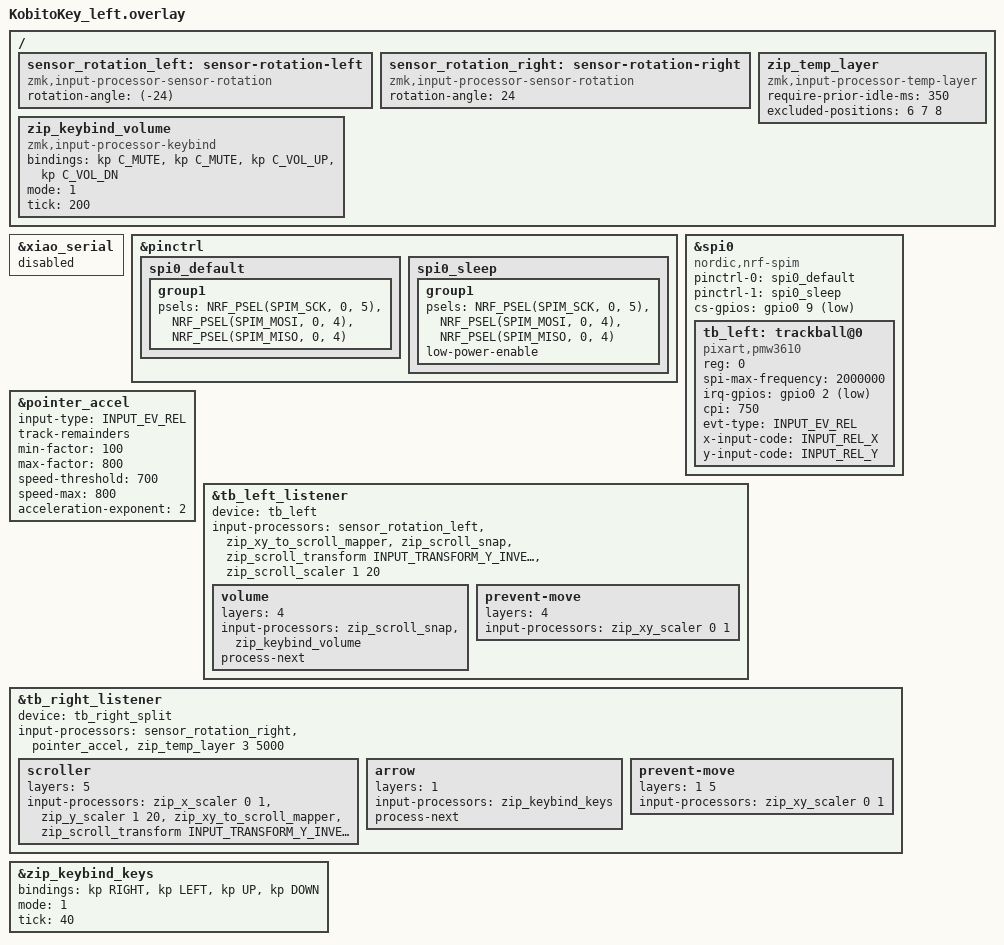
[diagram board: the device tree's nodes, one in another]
#include "kobitokey.dtsi"
#include <zephyr/dt-bindings/input/input-event-codes.h>
#include <input/processors.dtsi>
#include <input/processors/sensor_rotation.dtsi>
#include <behaviors/input_gestures_accel.dtsi>
#include <scroll-snap.dtsi>
#include <input/processors/zmk-input-processor-keybind.dtsi>

&xiao_serial { status = "disabled"; };

&pinctrl {
    spi0_default: spi0_default {
        group1 {
            psels = <NRF_PSEL(SPIM_SCK,  0, 5)>,
                    <NRF_PSEL(SPIM_MOSI, 0, 4)>,
                    <NRF_PSEL(SPIM_MISO, 0, 4)>;
        };
    };
    spi0_sleep: spi0_sleep {
        group1 {
            psels = <NRF_PSEL(SPIM_SCK,  0, 5)>,
                    <NRF_PSEL(SPIM_MOSI, 0, 4)>,
                    <NRF_PSEL(SPIM_MISO, 0, 4)>;
            low-power-enable;
        };
    };
};

&spi0 {
    status = "okay";
    compatible = "nordic,nrf-spim";
    pinctrl-0 = <&spi0_default>;
    pinctrl-1 = <&spi0_sleep>;
    pinctrl-names = "default", "sleep";
    cs-gpios = <&gpio0 9 GPIO_ACTIVE_LOW>;

    tb_left: trackball@0 {
        status = "okay";
        compatible = "pixart,pmw3610";
        reg = <0>;
        spi-max-frequency = <2000000>;
        irq-gpios = <&gpio0 2 (GPIO_ACTIVE_LOW | GPIO_PULL_UP)>;
        cpi = <750>; /* センサー感度 */

        evt-type = <INPUT_EV_REL>;
        x-input-code = <INPUT_REL_X>;
        y-input-code = <INPUT_REL_Y>;
    };
};

/ {
    sensor_rotation_left: sensor-rotation-left {
        compatible = "zmk,input-processor-sensor-rotation";
        status = "okay";
        #input-processor-cells = <0>;
        rotation-angle = <(-24)>;
    };

    sensor_rotation_right: sensor-rotation-right {
        compatible = "zmk,input-processor-sensor-rotation";
        #input-processor-cells = <0>;
        status = "okay";
        rotation-angle = <24>;
    };
};

&pointer_accel {
    input-type = <INPUT_EV_REL>;
    track-remainders;
    min-factor = <100>;
    max-factor = <800>;
    speed-threshold = <700>;
    speed-max = <800>;
    acceleration-exponent = <2>;
};

&tb_left_listener {
    status = "okay";
    device = <&tb_left>;

    input-processors =
            <&sensor_rotation_left>,
            <&zip_xy_to_scroll_mapper>,
            <&zip_scroll_snap>,
            <&zip_scroll_transform INPUT_TRANSFORM_Y_INVERT>,
            <&zip_scroll_scaler 1 20>;

    volume {
        layers = <4>;
        input-processors =
            <&zip_scroll_snap>,
            <&zip_keybind_volume>;
        process-next;
    };

    prevent-move {
        layers = <4>;
        input-processors = <&zip_xy_scaler 0 1>;
    };
};

/ {
  zip_keybind_volume: zip_keybind_volume {
    compatible = "zmk,input-processor-keybind";
    #input-processor-cells = <0>;
    bindings = <&kp C_MUTE>, <&kp C_MUTE>, <&kp C_VOL_UP>, <&kp C_VOL_DN>;
    mode = <1>;
    tick = <200>;
  };

  /omit-if-no-ref/ zip_temp_layer: zip_temp_layer {
    compatible = "zmk,input-processor-temp-layer";
    #input-processor-cells = <2>;
    require-prior-idle-ms = <350>;
  };
};

&tb_right_listener {
    status = "okay";
    device = <&tb_right_split>;

    input-processors =
        <&sensor_rotation_right>,
        <&pointer_accel>,
        <&zip_temp_layer 3 5000>; /* オートマウスレイヤーの指定とトラボ操作及びマウスボタン押下後に滞留する時間 */

    scroller {
        layers = <5>;
        input-processors =
            <&zip_x_scaler 0 1>,
            <&zip_y_scaler 1 20>,
            <&zip_xy_to_scroll_mapper>,
            <&zip_scroll_transform INPUT_TRANSFORM_Y_INVERT>;
    };

    arrow {
        layers = <1>;
        input-processors =
            <&zip_keybind_keys>;
        process-next;
    };

    prevent-move {
        layers = <1 5>;
        input-processors = <&zip_xy_scaler 0 1>;
    };
};
&zip_temp_layer {
    excluded-positions = <
        6
        7
        8
    >;
};

&zip_keybind_keys {
    bindings = <&kp RIGHT>, <&kp LEFT>, <&kp UP>, <&kp DOWN>;
    mode = <1>;         /* 4方向モード */
    tick = <40>;         /* 感度（要チューニング） */
    //tap-ms = <10>;       /* キー押下時間 */
};
